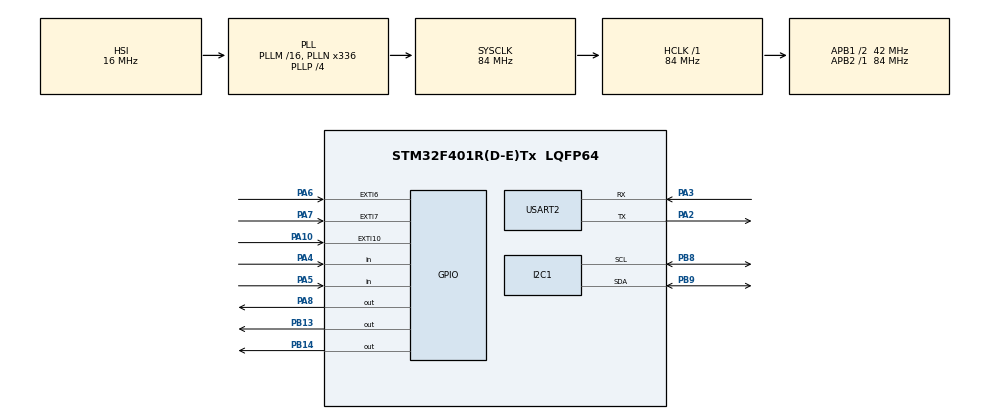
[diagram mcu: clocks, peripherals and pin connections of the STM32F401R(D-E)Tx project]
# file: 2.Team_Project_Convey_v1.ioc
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Dma.Request0=USART2_RX
Dma.Request1=USART2_TX
Dma.USART2_RX.0.Direction=DMA_PERIPH_TO_MEMORY
Dma.USART2_RX.0.FIFOMode=DMA_FIFOMODE_DISABLE
Dma.USART2_RX.0.Instance=DMA1_Stream5
Dma.USART2_RX.0.MemDataAlignment=DMA_MDATAALIGN_BYTE
Dma.USART2_RX.0.MemInc=DMA_MINC_ENABLE
Dma.USART2_RX.0.Mode=DMA_CIRCULAR
Dma.USART2_RX.0.PeriphDataAlignment=DMA_PDATAALIGN_BYTE
Dma.USART2_RX.0.PeriphInc=DMA_PINC_DISABLE
Dma.USART2_RX.0.Priority=DMA_PRIORITY_HIGH
Dma.USART2_TX.1.Direction=DMA_MEMORY_TO_PERIPH
Dma.USART2_TX.1.FIFOMode=DMA_FIFOMODE_DISABLE
Dma.USART2_TX.1.Instance=DMA1_Stream6
Dma.USART2_TX.1.MemDataAlignment=DMA_MDATAALIGN_BYTE
Dma.USART2_TX.1.MemInc=DMA_MINC_ENABLE
Dma.USART2_TX.1.Mode=DMA_NORMAL
Dma.USART2_TX.1.PeriphDataAlignment=DMA_PDATAALIGN_BYTE
Dma.USART2_TX.1.PeriphInc=DMA_PINC_DISABLE
Dma.USART2_TX.1.Priority=DMA_PRIORITY_LOW
FREERTOS.Tasks01=defaultTask,24,128,StartDefaultTask,Default,NULL,Dynamic,NULL,NULL;Task_System,24,256,StartTask02,Default,NULL,Dynamic,NULL,NULL;Task_FSM,40,512,StartTask03,Default,NULL,Dynamic,NULL,NULL
Mcu.Family=STM32F4
Mcu.Name=STM32F401R(D-E)Tx
Mcu.Package=LQFP64
NVIC.DMA1_Stream5_IRQn=true\:5\:0\:false\:false\:true\:true\:false\:true\:true
NVIC.DMA1_Stream6_IRQn=true\:5\:0\:false\:false\:true\:true\:false\:true\:true
NVIC.EXTI15_10_IRQn=true\:5\:0\:false\:false\:true\:true\:true\:true\:true
NVIC.EXTI9_5_IRQn=true\:5\:0\:false\:false\:true\:true\:true\:true\:true
NVIC.I2C1_ER_IRQn=true\:5\:0\:false\:false\:true\:true\:true\:true\:true
NVIC.I2C1_EV_IRQn=true\:5\:0\:false\:false\:true\:true\:true\:true\:true
NVIC.PriorityGroup=NVIC_PRIORITYGROUP_4
NVIC.TIM1_UP_TIM10_IRQn=true\:15\:0\:false\:false\:true\:false\:false\:true\:true
NVIC.TIM2_IRQn=true\:5\:0\:false\:false\:true\:true\:true\:true\:true
NVIC.TimeBase=TIM1_UP_TIM10_IRQn
NVIC.TimeBaseIP=TIM1
NVIC.USART2_IRQn=true\:5\:0\:false\:false\:true\:true\:true\:true\:true
PA10.GPIO_ModeDefaultEXTI=GPIO_MODE_IT_FALLING
PA10.GPIO_PuPd=GPIO_PULLUP
PA10.Signal=GPXTI10
PA13.Mode=Serial_Wire
PA13.Signal=SYS_JTMS-SWDIO
PA14.Mode=Serial_Wire
PA14.Signal=SYS_JTCK-SWCLK
PA2.Mode=Asynchronous
PA2.Signal=USART2_TX
PA3.Mode=Asynchronous
PA3.Signal=USART2_RX
PA4.GPIO_PuPd=GPIO_PULLUP
PA4.Signal=GPIO_Input
PA5.GPIO_PuPd=GPIO_PULLUP
PA5.Signal=GPIO_Input
PA6.GPIO_ModeDefaultEXTI=GPIO_MODE_IT_FALLING
PA6.GPIO_PuPd=GPIO_PULLUP
PA6.Signal=GPXTI6
PA7.GPIO_ModeDefaultEXTI=GPIO_MODE_IT_FALLING
PA7.GPIO_PuPd=GPIO_PULLUP
PA7.Signal=GPXTI7
PA8.GPIO_Speed=GPIO_SPEED_FREQ_VERY_HIGH
PA8.Signal=GPIO_Output
PB13.Signal=GPIO_Output
PB14.GPIO_Speed=GPIO_SPEED_FREQ_LOW
PB14.PinState=GPIO_PIN_SET
PB14.Signal=GPIO_Output
PB8.GPIO_Pu=GPIO_PULLUP
PB8.Mode=I2C
PB8.Signal=I2C1_SCL
PB9.GPIO_Pu=GPIO_PULLUP
PB9.Mode=I2C
PB9.Signal=I2C1_SDA
PC14-OSC32_IN.Mode=LSE-External-Oscillator
PC14-OSC32_IN.Signal=RCC_OSC32_IN
PC15-OSC32_OUT.Mode=LSE-External-Oscillator
PC15-OSC32_OUT.Signal=RCC_OSC32_OUT
PH0\ -\ OSC_IN.Mode=HSE-External-Oscillator
PH0\ -\ OSC_IN.Signal=RCC_OSC_IN
PH1\ -\ OSC_OUT.Mode=HSE-External-Oscillator
PH1\ -\ OSC_OUT.Signal=RCC_OSC_OUT
ProjectManager.HeapSize=0x200
ProjectManager.StackSize=0x400
ProjectManager.TargetToolchain=STM32CubeIDE
RCC.48MHZClocksFreq_Value=48000000
RCC.AHBFreq_Value=84000000
RCC.APB1CLKDivider=RCC_HCLK_DIV2
RCC.APB1Freq_Value=42000000
RCC.APB1TimFreq_Value=84000000
RCC.APB2Freq_Value=84000000
RCC.APB2TimFreq_Value=84000000
RCC.CortexFreq_Value=84000000
RCC.HCLKFreq_Value=84000000
RCC.HSE_VALUE=8000000
RCC.HSI_VALUE=16000000
RCC.PLLN=336
RCC.PLLP=RCC_PLLP_DIV4
RCC.PLLQ=7
RCC.SYSCLKFreq_VALUE=84000000
RCC.SYSCLKSource=RCC_SYSCLKSOURCE_PLLCLK
RCC.VCOOutputFreq_Value=336000000
TIM2.Period=999
TIM2.Prescaler=83
USART2.VirtualMode=VM_ASYNC
VP_FREERTOS_VS_CMSIS_V2.Mode=CMSIS_V2
VP_SYS_VS_tim1.Mode=TIM1
VP_TIM2_VS_ClockSourceINT.Mode=Internal
board=NUCLEO-F401RE

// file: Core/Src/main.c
/* USER CODE BEGIN Header */
/**
  ******************************************************************************
  * @file           : main.c
  * @brief          : Main program body
  ******************************************************************************
  * @attention
  *
  * Copyright (c) 2026 STMicroelectronics.
  * All rights reserved.
  *
  * This software is licensed under terms that can be found in the LICENSE file
  * in the root directory of this software component.
  * If no LICENSE file comes with this software, it is provided AS-IS.
  *
  ******************************************************************************
  */
/* USER CODE END Header */
#include "main.h"
#include "cmsis_os.h"

/* USER CODE BEGIN Includes */
#include "config.h"
#include "system_state.h"
#include "function.h"
/* USER CODE END Includes */

I2C_HandleTypeDef hi2c1;

TIM_HandleTypeDef htim2;

UART_HandleTypeDef huart2;
DMA_HandleTypeDef hdma_usart2_rx;
DMA_HandleTypeDef hdma_usart2_tx;

/* Definitions for defaultTask */
osThreadId_t defaultTaskHandle;
const osThreadAttr_t defaultTask_attributes = {
  .name = "defaultTask",
  .stack_size = 128 * 4,
  .priority = (osPriority_t) osPriorityNormal,
};
/* Definitions for Task_System */
osThreadId_t Task_SystemHandle;
const osThreadAttr_t Task_System_attributes = {
  .name = "Task_System",
  .stack_size = 256 * 4,
  .priority = (osPriority_t) osPriorityNormal,
};
/* Definitions for Task_FSM */
osThreadId_t Task_FSMHandle;
const osThreadAttr_t Task_FSM_attributes = {
  .name = "Task_FSM",
  .stack_size = 512 * 4,
  .priority = (osPriority_t) osPriorityHigh,
};
/* USER CODE BEGIN PV */

SystemStatus_t g_sys_status; // 전역 장부 실체 선언

/* USER CODE END PV */

void SystemClock_Config(void);
static void MX_GPIO_Init(void);
static void MX_DMA_Init(void);
static void MX_USART2_UART_Init(void);
static void MX_I2C1_Init(void);
static void MX_TIM2_Init(void);
void StartDefaultTask(void *argument);
void StartTask02(void *argument);
void StartTask03(void *argument);

int main(void)
{

  /* MCU Configuration--------------------------------------------------------*/

  /* Reset of all peripherals, Initializes the Flash interface and the Systick. */
  HAL_Init();

  /* Configure the system clock */
  SystemClock_Config();

  /* Initialize all configured peripherals */
  MX_GPIO_Init();
  MX_DMA_Init();
  MX_USART2_UART_Init();
  MX_I2C1_Init();
  MX_TIM2_Init();
  /* USER CODE BEGIN 2 */

    DRV_UART_Init();   // 1. 통신 시작 (DMA 수신 대기)
    DRV_I2C_Init();    // 2. PCA9685 및 서보 모터 초기화

  /* USER CODE END 2 */

  /* Init scheduler */
  osKernelInitialize();

  /* Create the thread(s) */
  /* creation of defaultTask */
  defaultTaskHandle = osThreadNew(StartDefaultTask, NULL, &defaultTask_attributes);

  /* creation of Task_System */
  Task_SystemHandle = osThreadNew(StartTask02, NULL, &Task_System_attributes);

  /* creation of Task_FSM */
  Task_FSMHandle = osThreadNew(StartTask03, NULL, &Task_FSM_attributes);

  /* Start scheduler */
  osKernelStart();

  /* We should never get here as control is now taken by the scheduler */

  /* Infinite loop */
  while (1)
  {

  }
}

void SystemClock_Config(void)
{
  RCC_OscInitTypeDef RCC_OscInitStruct = {0};
  RCC_ClkInitTypeDef RCC_ClkInitStruct = {0};

  /** Configure the main internal regulator output voltage
  */
  __HAL_RCC_PWR_CLK_ENABLE();
  __HAL_PWR_VOLTAGESCALING_CONFIG(PWR_REGULATOR_VOLTAGE_SCALE2);

  /** Initializes the RCC Oscillators according to the specified parameters
  * in the RCC_OscInitTypeDef structure.
  */
  RCC_OscInitStruct.OscillatorType = RCC_OSCILLATORTYPE_HSI;
  RCC_OscInitStruct.HSIState = RCC_HSI_ON;
  RCC_OscInitStruct.HSICalibrationValue = RCC_HSICALIBRATION_DEFAULT;
  RCC_OscInitStruct.PLL.PLLState = RCC_PLL_ON;
  RCC_OscInitStruct.PLL.PLLSource = RCC_PLLSOURCE_HSI;
  RCC_OscInitStruct.PLL.PLLM = 16;
  RCC_OscInitStruct.PLL.PLLN = 336;
  RCC_OscInitStruct.PLL.PLLP = RCC_PLLP_DIV4;
  RCC_OscInitStruct.PLL.PLLQ = 7;
  if (HAL_RCC_OscConfig(&RCC_OscInitStruct) != HAL_OK)
  {
    Error_Handler();
  }

  /** Initializes the CPU, AHB and APB buses clocks
  */
  RCC_ClkInitStruct.ClockType = RCC_CLOCKTYPE_HCLK|RCC_CLOCKTYPE_SYSCLK
                              |RCC_CLOCKTYPE_PCLK1|RCC_CLOCKTYPE_PCLK2;
  RCC_ClkInitStruct.SYSCLKSource = RCC_SYSCLKSOURCE_PLLCLK;
  RCC_ClkInitStruct.AHBCLKDivider = RCC_SYSCLK_DIV1;
  RCC_ClkInitStruct.APB1CLKDivider = RCC_HCLK_DIV2;
  RCC_ClkInitStruct.APB2CLKDivider = RCC_HCLK_DIV1;

  if (HAL_RCC_ClockConfig(&RCC_ClkInitStruct, FLASH_LATENCY_2) != HAL_OK)
  {
    Error_Handler();
  }
}

static void MX_I2C1_Init(void)
{

  hi2c1.Instance = I2C1;
  hi2c1.Init.ClockSpeed = 100000;
  hi2c1.Init.DutyCycle = I2C_DUTYCYCLE_2;
  hi2c1.Init.OwnAddress1 = 0;
  hi2c1.Init.AddressingMode = I2C_ADDRESSINGMODE_7BIT;
  hi2c1.Init.DualAddressMode = I2C_DUALADDRESS_DISABLE;
  hi2c1.Init.OwnAddress2 = 0;
  hi2c1.Init.GeneralCallMode = I2C_GENERALCALL_DISABLE;
  hi2c1.Init.NoStretchMode = I2C_NOSTRETCH_DISABLE;
  if (HAL_I2C_Init(&hi2c1) != HAL_OK)
  {
    Error_Handler();
  }

}

static void MX_TIM2_Init(void)
{

  TIM_ClockConfigTypeDef sClockSourceConfig = {0};
  TIM_MasterConfigTypeDef sMasterConfig = {0};

  htim2.Instance = TIM2;
  htim2.Init.Prescaler = 83;
  htim2.Init.CounterMode = TIM_COUNTERMODE_UP;
  htim2.Init.Period = 999;
  htim2.Init.ClockDivision = TIM_CLOCKDIVISION_DIV1;
  htim2.Init.AutoReloadPreload = TIM_AUTORELOAD_PRELOAD_DISABLE;
  if (HAL_TIM_Base_Init(&htim2) != HAL_OK)
  {
    Error_Handler();
  }
  sClockSourceConfig.ClockSource = TIM_CLOCKSOURCE_INTERNAL;
  if (HAL_TIM_ConfigClockSource(&htim2, &sClockSourceConfig) != HAL_OK)
  {
    Error_Handler();
  }
  sMasterConfig.MasterOutputTrigger = TIM_TRGO_RESET;
  sMasterConfig.MasterSlaveMode = TIM_MASTERSLAVEMODE_DISABLE;
  if (HAL_TIMEx_MasterConfigSynchronization(&htim2, &sMasterConfig) != HAL_OK)
  {
    Error_Handler();
  }

}

static void MX_USART2_UART_Init(void)
{

  huart2.Instance = USART2;
  huart2.Init.BaudRate = 115200;
  huart2.Init.WordLength = UART_WORDLENGTH_8B;
  huart2.Init.StopBits = UART_STOPBITS_1;
  huart2.Init.Parity = UART_PARITY_NONE;
  huart2.Init.Mode = UART_MODE_TX_RX;
  huart2.Init.HwFlowCtl = UART_HWCONTROL_NONE;
  huart2.Init.OverSampling = UART_OVERSAMPLING_16;
  if (HAL_UART_Init(&huart2) != HAL_OK)
  {
    Error_Handler();
  }

}

static void MX_DMA_Init(void)
{

  /* DMA controller clock enable */
  __HAL_RCC_DMA1_CLK_ENABLE();

  /* DMA interrupt init */
  /* DMA1_Stream5_IRQn interrupt configuration */
  HAL_NVIC_SetPriority(DMA1_Stream5_IRQn, 5, 0);
  HAL_NVIC_EnableIRQ(DMA1_Stream5_IRQn);
  /* DMA1_Stream6_IRQn interrupt configuration */
  HAL_NVIC_SetPriority(DMA1_Stream6_IRQn, 5, 0);
  HAL_NVIC_EnableIRQ(DMA1_Stream6_IRQn);

}

static void MX_GPIO_Init(void)
{
  GPIO_InitTypeDef GPIO_InitStruct = {0};

  /* GPIO Ports Clock Enable */
  __HAL_RCC_GPIOC_CLK_ENABLE();
  __HAL_RCC_GPIOH_CLK_ENABLE();
  __HAL_RCC_GPIOA_CLK_ENABLE();
  __HAL_RCC_GPIOB_CLK_ENABLE();

  /*Configure GPIO pin Output Level */
  HAL_GPIO_WritePin(GPIOB, GPIO_PIN_13, GPIO_PIN_RESET);

  /*Configure GPIO pin Output Level */
  HAL_GPIO_WritePin(GPIOB, GPIO_PIN_14, GPIO_PIN_SET);

  /*Configure GPIO pin Output Level */
  HAL_GPIO_WritePin(GPIOA, GPIO_PIN_8, GPIO_PIN_RESET);

  /*Configure GPIO pins : PA4 PA5 */
  GPIO_InitStruct.Pin = GPIO_PIN_4|GPIO_PIN_5;
  GPIO_InitStruct.Mode = GPIO_MODE_INPUT;
  GPIO_InitStruct.Pull = GPIO_PULLUP;
  HAL_GPIO_Init(GPIOA, &GPIO_InitStruct);

  /*Configure GPIO pins : PA6 PA7 PA10 */
  GPIO_InitStruct.Pin = GPIO_PIN_6|GPIO_PIN_7|GPIO_PIN_10;
  GPIO_InitStruct.Mode = GPIO_MODE_IT_FALLING;
  GPIO_InitStruct.Pull = GPIO_PULLUP;
  HAL_GPIO_Init(GPIOA, &GPIO_InitStruct);

  /*Configure GPIO pins : PB13 PB14 */
  GPIO_InitStruct.Pin = GPIO_PIN_13|GPIO_PIN_14;
  GPIO_InitStruct.Mode = GPIO_MODE_OUTPUT_PP;
  GPIO_InitStruct.Pull = GPIO_NOPULL;
  GPIO_InitStruct.Speed = GPIO_SPEED_FREQ_LOW;
  HAL_GPIO_Init(GPIOB, &GPIO_InitStruct);

  /*Configure GPIO pin : PA8 */
  GPIO_InitStruct.Pin = GPIO_PIN_8;
  GPIO_InitStruct.Mode = GPIO_MODE_OUTPUT_PP;
  GPIO_InitStruct.Pull = GPIO_NOPULL;
  GPIO_InitStruct.Speed = GPIO_SPEED_FREQ_VERY_HIGH;
  HAL_GPIO_Init(GPIOA, &GPIO_InitStruct);

  /* EXTI interrupt init*/
  HAL_NVIC_SetPriority(EXTI9_5_IRQn, 5, 0);
  HAL_NVIC_EnableIRQ(EXTI9_5_IRQn);

  HAL_NVIC_SetPriority(EXTI15_10_IRQn, 5, 0);
  HAL_NVIC_EnableIRQ(EXTI15_10_IRQn);

}

void StartDefaultTask(void *argument)
{
  /* USER CODE BEGIN 5 */
  /* Infinite loop */
  for(;;)
  {
    osDelay(10);
  }
  /* USER CODE END 5 */
}

void StartTask02(void *argument)
{
  /* USER CODE BEGIN StartTask02 */
  /* Infinite loop */
  for(;;)
  {
	TASK_System_Execute();
    osDelay(1);
  }
  /* USER CODE END StartTask02 */
}

void StartTask03(void *argument)
{
  /* USER CODE BEGIN StartTask03 */
  /* Infinite loop */
  for(;;)
  {
	APP_FSM_Execute();
    osDelay(10);
  }
  /* USER CODE END StartTask03 */
}

void HAL_TIM_PeriodElapsedCallback(TIM_HandleTypeDef *htim)
{
  if (htim->Instance == TIM1) {
    HAL_IncTick();
  }
}

void Error_Handler(void)
{
  __disable_irq();
  while (1)
  {
  }
}
